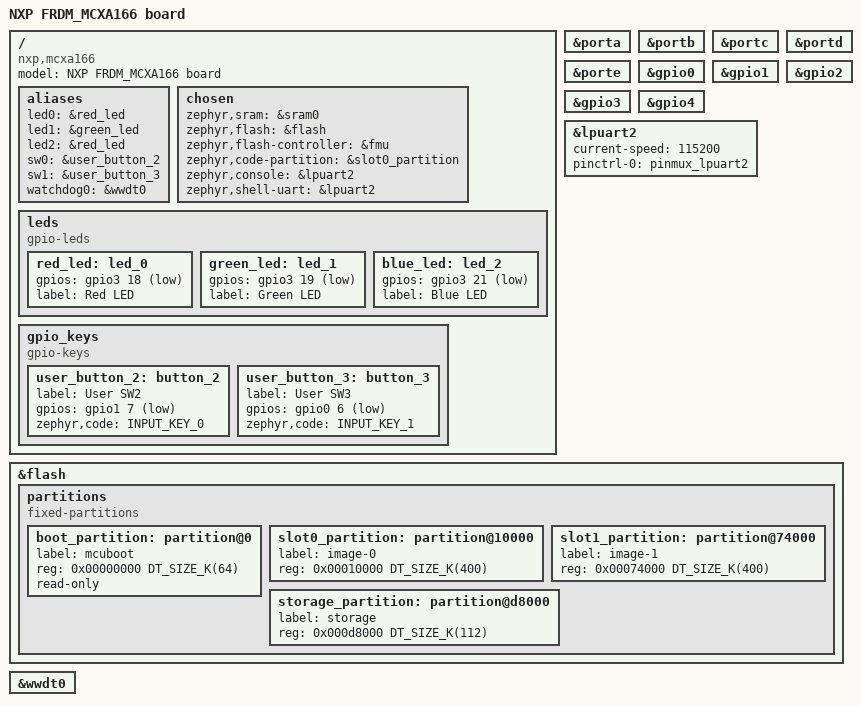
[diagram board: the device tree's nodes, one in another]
/*
 * Copyright 2025 NXP
 *
 * SPDX-License-Identifier: Apache-2.0
 */

/dts-v1/;

#include <nxp/nxp_mcxa166.dtsi>
#include "frdm_mcxa166-pinctrl.dtsi"
#include <zephyr/dt-bindings/input/input-event-codes.h>

/ {
	model = "NXP FRDM_MCXA166 board";
	compatible = "nxp,mcxa166", "nxp,mcx";

	aliases{
		led0 = &red_led;
		led1 = &green_led;
		led2 = &red_led;
		sw0 = &user_button_2;
		sw1 = &user_button_3;
		watchdog0 = &wwdt0;
	};

	chosen {
		zephyr,sram = &sram0;
		zephyr,flash = &flash;
		zephyr,flash-controller = &fmu;
		zephyr,code-partition = &slot0_partition;
		zephyr,console = &lpuart2;
		zephyr,shell-uart = &lpuart2;
	};

	leds {
		compatible = "gpio-leds";

		red_led: led_0 {
			gpios = <&gpio3 18 GPIO_ACTIVE_LOW>;
			label = "Red LED";
		};

		green_led: led_1 {
			gpios = <&gpio3 19 GPIO_ACTIVE_LOW>;
			label = "Green LED";
		};

		blue_led: led_2 {
			gpios = <&gpio3 21 GPIO_ACTIVE_LOW>;
			label = "Blue LED";
		};
	};

	gpio_keys {
		compatible = "gpio-keys";

		user_button_2: button_2 {
			label = "User SW2";
			gpios = <&gpio1 7 GPIO_ACTIVE_LOW>;
			zephyr,code = <INPUT_KEY_0>;
		};

		user_button_3: button_3 {
			label = "User SW3";
			gpios = <&gpio0 6 GPIO_ACTIVE_LOW>;
			zephyr,code = <INPUT_KEY_1>;
		};
	};

};

&porta {
	status = "okay";
};

&portb {
	status = "okay";
};

&portc {
	status = "okay";
};

&portd {
	status = "okay";
};

&porte {
	status = "okay";
};

&gpio0 {
	status = "okay";
};

&gpio1 {
	status = "okay";
};

&gpio2 {
	status = "okay";
};

&gpio3 {
	status = "okay";
};

&gpio4 {
	status = "okay";
};

&lpuart2 {
	status = "okay";
	current-speed = <115200>;
	pinctrl-0 = <&pinmux_lpuart2>;
	pinctrl-names = "default";
};

&flash {
	partitions {
		compatible = "fixed-partitions";
		#address-cells = <1>;
		#size-cells = <1>;

		boot_partition: partition@0 {
			label = "mcuboot";
			reg = <0x00000000 DT_SIZE_K(64)>;
			read-only;
		};
		slot0_partition: partition@10000 {
			label = "image-0";
			reg = <0x00010000 DT_SIZE_K(400)>;
		};
		slot1_partition: partition@74000 {
			label = "image-1";
			reg = <0x00074000 DT_SIZE_K(400)>;
		};
		storage_partition: partition@d8000 {
			label = "storage";
			reg = <0x000d8000 DT_SIZE_K(112)>;
		};
	};
};

&wwdt0 {
	status = "okay";
};
